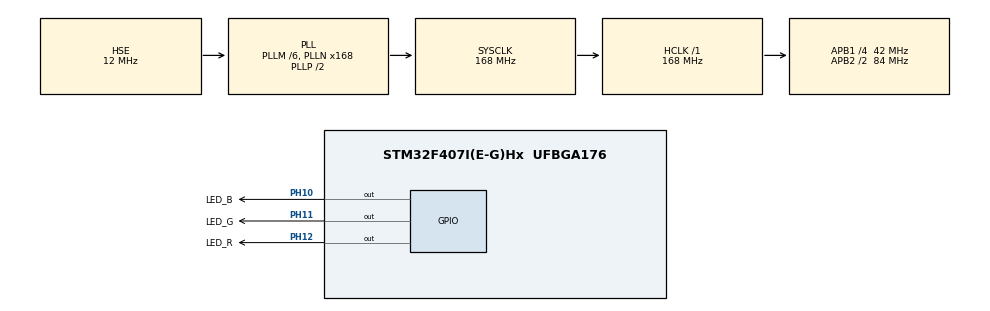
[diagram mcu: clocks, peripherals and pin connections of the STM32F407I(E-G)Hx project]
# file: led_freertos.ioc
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FREERTOS.Tasks01=defaultTask,0,128,StartDefaultTask,Default,NULL,Dynamic,NULL,NULL
Mcu.Family=STM32F4
Mcu.Name=STM32F407I(E-G)Hx
Mcu.Package=UFBGA176
NVIC.PriorityGroup=NVIC_PRIORITYGROUP_4
PA13.Mode=Serial_Wire
PA13.Signal=SYS_JTMS-SWDIO
PA14.Mode=Serial_Wire
PA14.Signal=SYS_JTCK-SWCLK
PH0-OSC_IN.Mode=HSE-External-Oscillator
PH0-OSC_IN.Signal=RCC_OSC_IN
PH1-OSC_OUT.Mode=HSE-External-Oscillator
PH1-OSC_OUT.Signal=RCC_OSC_OUT
PH10.GPIO_Label=LED_B
PH10.Signal=GPIO_Output
PH11.GPIO_Label=LED_G
PH11.Signal=GPIO_Output
PH12.GPIO_Label=LED_R
PH12.Signal=GPIO_Output
ProjectManager.HeapSize=0x200
ProjectManager.StackSize=0x400
ProjectManager.TargetToolchain=MDK-ARM V5.32
RCC.48MHZClocksFreq_Value=84000000
RCC.AHBFreq_Value=168000000
RCC.APB1CLKDivider=RCC_HCLK_DIV4
RCC.APB1Freq_Value=42000000
RCC.APB1TimFreq_Value=84000000
RCC.APB2CLKDivider=RCC_HCLK_DIV2
RCC.APB2Freq_Value=84000000
RCC.APB2TimFreq_Value=168000000
RCC.CortexFreq_Value=168000000
RCC.HCLKFreq_Value=168000000
RCC.HSE_VALUE=12000000
RCC.HSI_VALUE=16000000
RCC.LSE_VALUE=32768
RCC.PLLM=6
RCC.PLLN=168
RCC.PLLSourceVirtual=RCC_PLLSOURCE_HSE
RCC.SYSCLKFreq_VALUE=168000000
RCC.SYSCLKSource=RCC_SYSCLKSOURCE_PLLCLK
RCC.VCOOutputFreq_Value=336000000
VP_FREERTOS_VS_CMSIS_V1.Mode=CMSIS_V1
board=custom

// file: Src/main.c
/* USER CODE BEGIN Header */
/**
  ******************************************************************************
  * @file           : main.c
  * @brief          : Main program body
  ******************************************************************************
  * @attention
  *
  * Copyright (c) 2022 STMicroelectronics.
  * All rights reserved.
  *
  * This software is licensed under terms that can be found in the LICENSE file
  * in the root directory of this software component.
  * If no LICENSE file comes with this software, it is provided AS-IS.
  *
  ******************************************************************************
  */
/* USER CODE END Header */
#include "main.h"
#include "cmsis_os.h"
#include "gpio.h"

void SystemClock_Config(void);
void MX_FREERTOS_Init(void);

int main(void)
{

  /* MCU Configuration--------------------------------------------------------*/

  /* Reset of all peripherals, Initializes the Flash interface and the Systick. */
  HAL_Init();

  /* Configure the system clock */
  SystemClock_Config();

  /* Initialize all configured peripherals */
  MX_GPIO_Init();

  /* Call init function for freertos objects (in freertos.c) */
  MX_FREERTOS_Init();

  /* Start scheduler */
  osKernelStart();

  /* We should never get here as control is now taken by the scheduler */
  /* Infinite loop */
  while (1)
  {

  }
  return 0;
}

void SystemClock_Config(void)
{
  RCC_OscInitTypeDef RCC_OscInitStruct = {0};
  RCC_ClkInitTypeDef RCC_ClkInitStruct = {0};

  /** Configure the main internal regulator output voltage
  */
  __HAL_RCC_PWR_CLK_ENABLE();
  __HAL_PWR_VOLTAGESCALING_CONFIG(PWR_REGULATOR_VOLTAGE_SCALE1);

  /** Initializes the RCC Oscillators according to the specified parameters
  * in the RCC_OscInitTypeDef structure.
  */
  RCC_OscInitStruct.OscillatorType = RCC_OSCILLATORTYPE_HSE;
  RCC_OscInitStruct.HSEState = RCC_HSE_ON;
  RCC_OscInitStruct.PLL.PLLState = RCC_PLL_ON;
  RCC_OscInitStruct.PLL.PLLSource = RCC_PLLSOURCE_HSE;
  RCC_OscInitStruct.PLL.PLLM = 6;
  RCC_OscInitStruct.PLL.PLLN = 168;
  RCC_OscInitStruct.PLL.PLLP = RCC_PLLP_DIV2;
  RCC_OscInitStruct.PLL.PLLQ = 4;
  if (HAL_RCC_OscConfig(&RCC_OscInitStruct) != HAL_OK)
  {
    Error_Handler();
  }

  /** Initializes the CPU, AHB and APB buses clocks
  */
  RCC_ClkInitStruct.ClockType = RCC_CLOCKTYPE_HCLK|RCC_CLOCKTYPE_SYSCLK
                              |RCC_CLOCKTYPE_PCLK1|RCC_CLOCKTYPE_PCLK2;
  RCC_ClkInitStruct.SYSCLKSource = RCC_SYSCLKSOURCE_PLLCLK;
  RCC_ClkInitStruct.AHBCLKDivider = RCC_SYSCLK_DIV1;
  RCC_ClkInitStruct.APB1CLKDivider = RCC_HCLK_DIV4;
  RCC_ClkInitStruct.APB2CLKDivider = RCC_HCLK_DIV2;

  if (HAL_RCC_ClockConfig(&RCC_ClkInitStruct, FLASH_LATENCY_5) != HAL_OK)
  {
    Error_Handler();
  }
}

void Error_Handler(void)
{
  __disable_irq();
  while (1)
  {
  }
}

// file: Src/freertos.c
/* USER CODE BEGIN Header */
/**
  ******************************************************************************
  * File Name          : freertos.c
  * Description        : Code for freertos applications
  ******************************************************************************
  * @attention
  *
  * Copyright (c) 2022 STMicroelectronics.
  * All rights reserved.
  *
  * This software is licensed under terms that can be found in the LICENSE file
  * in the root directory of this software component.
  * If no LICENSE file comes with this software, it is provided AS-IS.
  *
  ******************************************************************************
  */
/* USER CODE END Header */

#include "FreeRTOS.h"
#include "task.h"
#include "main.h"
#include "cmsis_os.h"

osThreadId LED_R_HANDLE,LED_G_HANDLE,LED_B_HANDLE;

void led_r_task(void const * argument);
void led_g_task(void const * argument);
void led_b_task(void const * argument);

void MX_FREERTOS_Init(void); /* (MISRA C 2004 rule 8.1) */

/* GetIdleTaskMemory prototype (linked to static allocation support) */
void vApplicationGetIdleTaskMemory( StaticTask_t **ppxIdleTaskTCBBuffer, StackType_t **ppxIdleTaskStackBuffer, uint32_t *pulIdleTaskStackSize );

/* USER CODE BEGIN GET_IDLE_TASK_MEMORY */
static StaticTask_t xIdleTaskTCBBuffer;
static StackType_t xIdleStack[configMINIMAL_STACK_SIZE];

void vApplicationGetIdleTaskMemory( StaticTask_t **ppxIdleTaskTCBBuffer, StackType_t **ppxIdleTaskStackBuffer, uint32_t *pulIdleTaskStackSize )
{
  *ppxIdleTaskTCBBuffer = &xIdleTaskTCBBuffer;
  *ppxIdleTaskStackBuffer = &xIdleStack[0];
  *pulIdleTaskStackSize = configMINIMAL_STACK_SIZE;
  /* place for user code */
}
/* USER CODE END GET_IDLE_TASK_MEMORY */

void MX_FREERTOS_Init(void) {

  /* Create the thread(s) */
  /* definition and creation of defaultTask */
  osThreadDef(LED_R,led_r_task, osPriorityNormal, 0, 128);
  LED_R_HANDLE = osThreadCreate(osThread(LED_R), NULL);

  osThreadDef(LED_G,led_g_task, osPriorityNormal, 0, 128);
  LED_G_HANDLE = osThreadCreate(osThread(LED_G), NULL);

  osThreadDef(LED_B,led_b_task, osPriorityNormal, 0, 128);
  LED_B_HANDLE = osThreadCreate(osThread(LED_B), NULL);

}

/* USER CODE BEGIN Application */
void led_b_task(void const *argument){
  while(1)
  {
    HAL_GPIO_WritePin(LED_B_GPIO_Port,LED_B_Pin,GPIO_PIN_RESET);
    osDelay(500);
    HAL_GPIO_WritePin(LED_B_GPIO_Port,LED_B_Pin,GPIO_PIN_SET);
    osDelay(500);
  }
}

void led_g_task(void const *argument){
  while(1)
  {
    HAL_GPIO_WritePin(LED_G_GPIO_Port,LED_G_Pin,GPIO_PIN_RESET);
    osDelay(500);
    HAL_GPIO_WritePin(LED_G_GPIO_Port,LED_G_Pin,GPIO_PIN_SET);
    osDelay(500);
  }
}

void led_r_task(void const *argument){
  while(1)
  {
    HAL_GPIO_WritePin(LED_R_GPIO_Port,LED_R_Pin,GPIO_PIN_RESET);
    osDelay(500);
    HAL_GPIO_WritePin(LED_R_GPIO_Port,LED_R_Pin,GPIO_PIN_SET);
    osDelay(500);
  }
}
/* USER CODE END Application */
